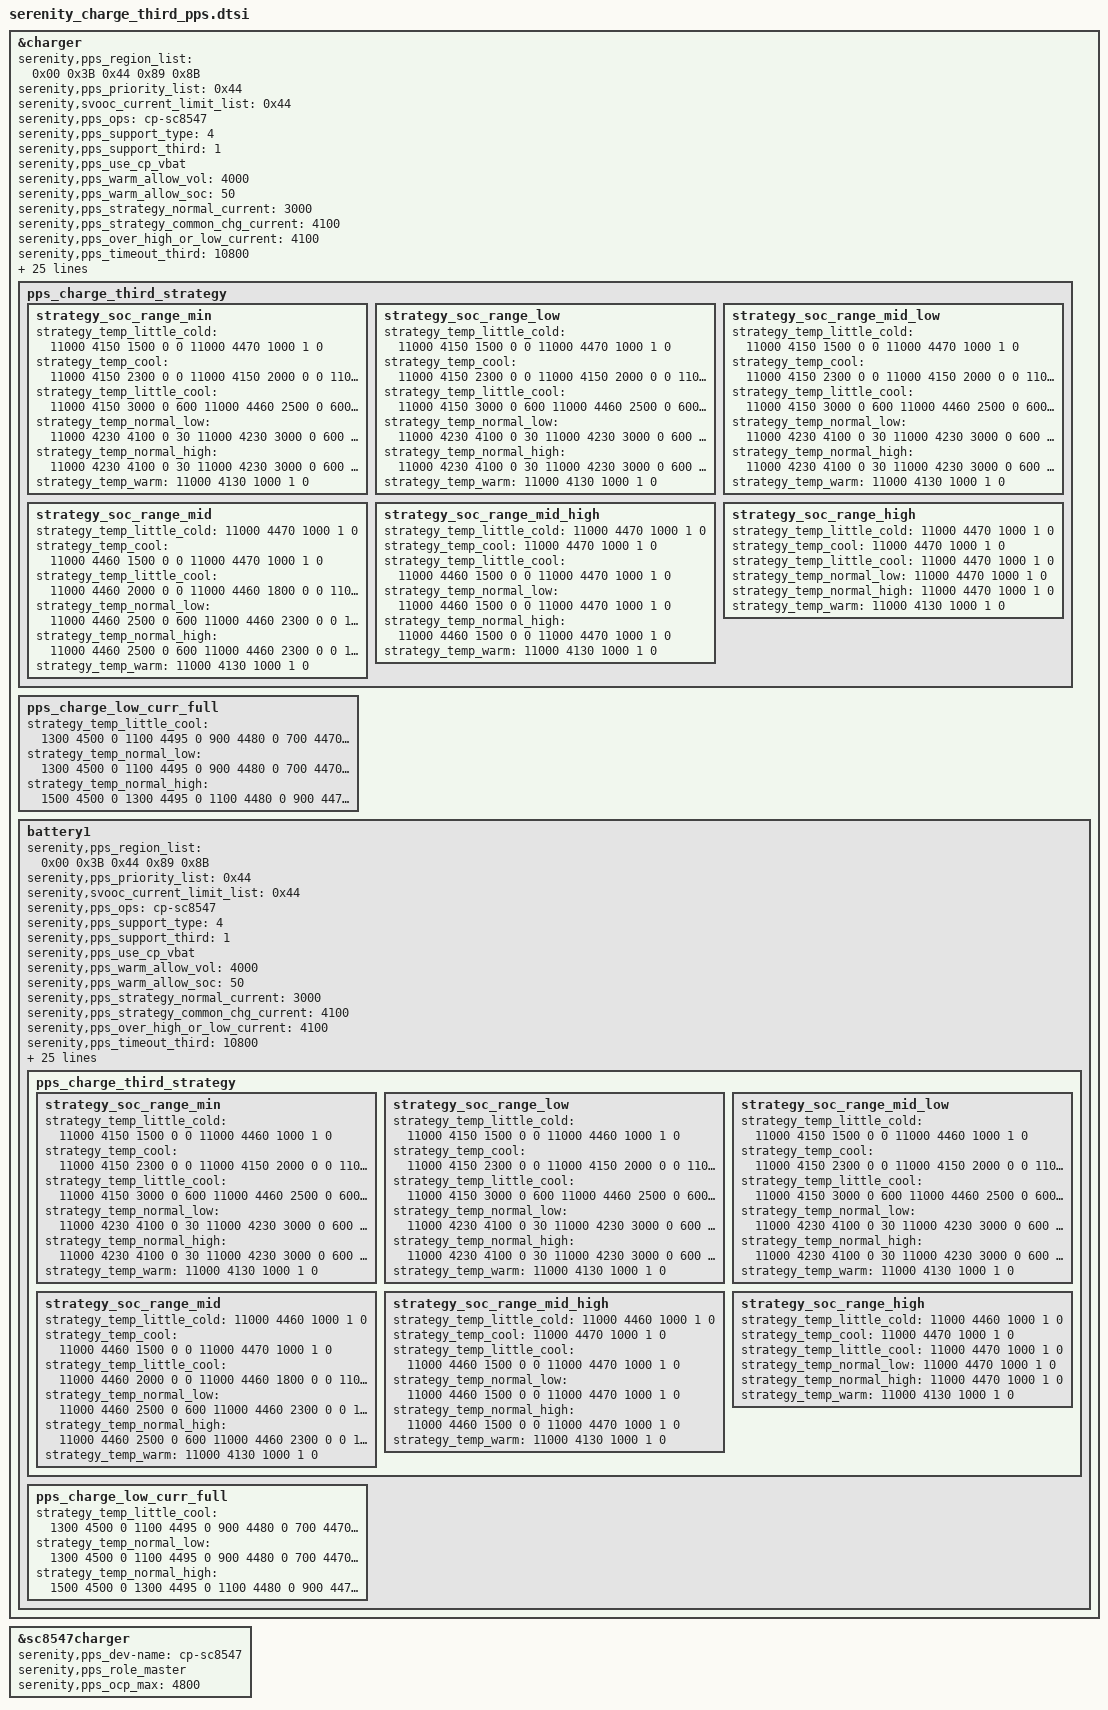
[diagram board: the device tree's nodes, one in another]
//#ifdef SERENITY_FEATURE_CHG_BASIC
&charger {
	// 3rd PPS
	serenity,pps_region_list = <0x00 0x3B 0x44 0x89 0x8B>;
	serenity,pps_priority_list = <0x44>;
	serenity,svooc_current_limit_list = <0x44>;
	serenity,pps_ops = "cp-sc8547";
	serenity,pps_support_type = <4>;
	serenity,pps_support_third = <1>;
	serenity,pps_use_cp_vbat;
	serenity,pps_warm_allow_vol = <4000>;
	serenity,pps_warm_allow_soc = <50>;
	serenity,pps_strategy_normal_current = <3000>;//3A
	serenity,pps_strategy_common_chg_current = <4100>;//4.1A
	serenity,pps_over_high_or_low_current = <4100>;
	serenity,pps_timeout_third = <10800>;
	serenity,pps_timeout_serenity = <7200>;
	serenity,pps_ibat_over_third = <8200>;
	serenity,pps_ibat_over_serenity = <17000>;
	serenity,pps_full_ffc_vbat = <4500>;
	serenity,pps_full_cool_sw_vbat = <4460>;
	serenity,pps_full_normal_sw_vbat = <4460>;
	serenity,pps_full_normal_hw_vbat = <4470>;
	serenity,pps_full_warm_vbat = <4130>;
	serenity,pps_full_cool_sw_vbat_third = <4460>;
	serenity,pps_full_normal_sw_vbat_third = <4460>;
	serenity,pps_full_normal_hw_vbat_third = <4470>;
	serenity,pps_r_default = <120 10 10 15 15 15 15>;
	serenity,pps_rmos_mohm = <4>;
	serenity,pps_exit_ms = <500>;
	serenity,pps_r_limit = <280 200 140 90 50>;
	serenity,pps_strategy_batt_high_temp = <385 395 420 375 385 410>;
	serenity,pps_strategy_high_current = <3000 3000 2000 3000 3000 3000>;
	serenity,pps_charge_strategy_soc = <0 15 35 50 75 85 90>;
	serenity,pps_charge_strategy_temp = <0 50 120 160 350 430 530>;
	serenity,pps_low_curr_full_strategy_temp = <120 200 350 430>;

	pps_charge_third_strategy {
		// 0 ~ 15
		strategy_soc_range_min {
			strategy_temp_little_cold =	<11000 4150 1500 0 0
							 11000 4470 1000 1 0>;
			strategy_temp_cool =		<11000 4150 2300 0 0
							 11000 4150 2000 0 0
							 11000 4460 1500 0 0
							 11000 4470 1000 1 0>;
			strategy_temp_little_cool =	<11000 4150 3000 0 600
							 11000 4460 2500 0 600
							 11000 4460 2300 0 0
							 11000 4460 2000 0 0
							 11000 4460 1800 0 0
							 11000 4460 1500 0 0
							 11000 4470 1000 1 0>;
			strategy_temp_normal_low =	<11000 4230 4100 0 30
							 11000 4230 3000 0 600
							 11000 4460 2500 0 600
							 11000 4460 2300 0 0
							 11000 4460 2000 0 0
							 11000 4460 1800 0 0
							 11000 4460 1500 0 0
							 11000 4470 1000 1 0>;
			strategy_temp_normal_high =	<11000 4230 4100 0 30
							 11000 4230 3000 0 600
							 11000 4460 2500 0 600
							 11000 4460 2300 0 0
							 11000 4460 2000 0 0
							 11000 4460 1800 0 0
							 11000 4460 1500 0 0
							 11000 4470 1000 1 0>;
			strategy_temp_warm =		<11000 4130 1000 1 0>;
		};
		// 15 ~ 35
		strategy_soc_range_low {
			strategy_temp_little_cold =	<11000 4150 1500 0 0
							 11000 4470 1000 1 0>;
			strategy_temp_cool =		<11000 4150 2300 0 0
							 11000 4150 2000 0 0
							 11000 4460 1500 0 0
							 11000 4470 1000 1 0>;
			strategy_temp_little_cool =	<11000 4150 3000 0 600
							 11000 4460 2500 0 600
							 11000 4460 2300 0 0
							 11000 4460 2000 0 0
							 11000 4460 1800 0 0
							 11000 4460 1500 0 0
							 11000 4470 1000 1 0>;
			strategy_temp_normal_low =	<11000 4230 4100 0 30
							 11000 4230 3000 0 600
							 11000 4460 2500 0 600
							 11000 4460 2300 0 0
							 11000 4460 2000 0 0
							 11000 4460 1800 0 0
							 11000 4460 1500 0 0
							 11000 4470 1000 1 0>;
			strategy_temp_normal_high =	<11000 4230 4100 0 30
							 11000 4230 3000 0 600
							 11000 4460 2500 0 600
							 11000 4460 2300 0 0
							 11000 4460 2000 0 0
							 11000 4460 1800 0 0
							 11000 4460 1500 0 0
							 11000 4470 1000 1 0>;
			strategy_temp_warm =		<11000 4130 1000 1 0>;
		};
		// 35 ~ 50
		strategy_soc_range_mid_low {
			strategy_temp_little_cold =	<11000 4150 1500 0 0
							 11000 4470 1000 1 0>;
			strategy_temp_cool =		<11000 4150 2300 0 0
							 11000 4150 2000 0 0
							 11000 4460 1500 0 0
							 11000 4470 1000 1 0>;
			strategy_temp_little_cool =	<11000 4150 3000 0 600
							 11000 4460 2500 0 600
							 11000 4460 2300 0 0
							 11000 4460 2000 0 0
							 11000 4460 1800 0 0
							 11000 4460 1500 0 0
							 11000 4470 1000 1 0>;
			strategy_temp_normal_low =	<11000 4230 4100 0 30
							 11000 4230 3000 0 600
							 11000 4460 2500 0 600
							 11000 4460 2300 0 0
							 11000 4460 2000 0 0
							 11000 4460 1800 0 0
							 11000 4460 1500 0 0
							 11000 4470 1000 1 0>;
			strategy_temp_normal_high =	<11000 4230 4100 0 30
							 11000 4230 3000 0 600
							 11000 4460 2500 0 600
							 11000 4460 2300 0 0
							 11000 4460 2000 0 0
							 11000 4460 1800 0 0
							 11000 4460 1500 0 0
							 11000 4470 1000 1 0>;
			strategy_temp_warm =		<11000 4130 1000 1 0>;
		};
		// 50 ~ 75
		strategy_soc_range_mid {
			strategy_temp_little_cold =	<11000 4470 1000 1 0>;
			strategy_temp_cool =		<11000 4460 1500 0 0
							 11000 4470 1000 1 0>;
			strategy_temp_little_cool =	<11000 4460 2000 0 0
							 11000 4460 1800 0 0
							 11000 4460 1500 0 0
							 11000 4470 1000 1 0>;
			strategy_temp_normal_low =	<11000 4460 2500 0 600
							 11000 4460 2300 0 0
							 11000 4460 2000 0 0
							 11000 4460 1800 0 0
							 11000 4460 1500 0 0
							 11000 4470 1000 1 0>;
			strategy_temp_normal_high =	<11000 4460 2500 0 600
							 11000 4460 2300 0 0
							 11000 4460 2000 0 0
							 11000 4460 1800 0 0
							 11000 4460 1500 0 0
							 11000 4470 1000 1 0>;
			strategy_temp_warm =		<11000 4130 1000 1 0>;
		};
		// 75 ~ 85
		strategy_soc_range_mid_high {
			strategy_temp_little_cold =	<11000 4470 1000 1 0>;
			strategy_temp_cool =		<11000 4470 1000 1 0>;
			strategy_temp_little_cool =	<11000 4460 1500 0 0
							 11000 4470 1000 1 0>;
			strategy_temp_normal_low =	<11000 4460 1500 0 0
							 11000 4470 1000 1 0>;
			strategy_temp_normal_high =	<11000 4460 1500 0 0
							 11000 4470 1000 1 0>;
			strategy_temp_warm =		<11000 4130 1000 1 0>;
		};
		// 85 ~ 90
		strategy_soc_range_high {
			strategy_temp_little_cold =	<11000 4470 1000 1 0>;
			strategy_temp_cool =		<11000 4470 1000 1 0>;
			strategy_temp_little_cool =	<11000 4470 1000 1 0>;
			strategy_temp_normal_low =	<11000 4470 1000 1 0>;
			strategy_temp_normal_high =	<11000 4470 1000 1 0>;
			strategy_temp_warm =		<11000 4130 1000 1 0>;
		};
	};
	pps_charge_low_curr_full {
		strategy_temp_little_cool = 	<1300 4500 0
						 1100 4495 0
						 900 4480 0
						 700 4470 0
						 500 4460 1>;
		strategy_temp_normal_low =		<1300 4500 0
						 1100 4495 0
						 900 4480 0
						 700 4470 0
						 500 4460 1>;
		strategy_temp_normal_high = 	<1500 4500 0
						 1300 4495 0
						 1100 4480 0
						 900 4470 0
						 700 4460 1>;
	};
};

&charger {
	battery1 {
		// 3rd PPS
		serenity,pps_region_list = <0x00 0x3B 0x44 0x89 0x8B>;
		serenity,pps_priority_list = <0x44>;
		serenity,svooc_current_limit_list = <0x44>;
		serenity,pps_ops = "cp-sc8547";
		serenity,pps_support_type = <4>;
		serenity,pps_support_third = <1>;
		serenity,pps_use_cp_vbat;
		serenity,pps_warm_allow_vol = <4000>;
		serenity,pps_warm_allow_soc = <50>;
		serenity,pps_strategy_normal_current = <3000>;//3A
		serenity,pps_strategy_common_chg_current = <4100>;//4.1A
		serenity,pps_over_high_or_low_current = <4100>;
		serenity,pps_timeout_third = <10800>;
		serenity,pps_timeout_serenity = <7200>;
		serenity,pps_ibat_over_third = <8200>;
		serenity,pps_ibat_over_serenity = <17000>;
		serenity,pps_full_ffc_vbat = <4500>;
		serenity,pps_full_cool_sw_vbat = <4460>;
		serenity,pps_full_normal_sw_vbat = <4460>;
		serenity,pps_full_normal_hw_vbat = <4470>;
		serenity,pps_full_warm_vbat = <4130>;
		serenity,pps_full_cool_sw_vbat_third = <4460>;
		serenity,pps_full_normal_sw_vbat_third = <4460>;
		serenity,pps_full_normal_hw_vbat_third = <4470>;
		serenity,pps_r_default = <120 10 10 15 15 15 15>;
		serenity,pps_rmos_mohm = <4>;
		serenity,pps_exit_ms = <500>;
		serenity,pps_r_limit = <280 200 140 90 50>;
		serenity,pps_strategy_batt_high_temp = <385 395 420 375 385 410>;
		serenity,pps_strategy_high_current = <3000 3000 2000 3000 3000 3000>;
		serenity,pps_charge_strategy_soc = <0 15 35 50 75 85 90>;
		serenity,pps_charge_strategy_temp = <0 50 120 160 350 430 530>;
		serenity,pps_low_curr_full_strategy_temp = <120 200 350 430>;

		pps_charge_third_strategy {
			// 0 ~ 15
			strategy_soc_range_min {
				strategy_temp_little_cold =	<11000 4150 1500 0 0
								11000 4460 1000 1 0>;
				strategy_temp_cool =		<11000 4150 2300 0 0
								11000 4150 2000 0 0
								11000 4460 1500 0 0
								11000 4470 1000 1 0>;
				strategy_temp_little_cool =	<11000 4150 3000 0 600
								11000 4460 2500 0 600
								11000 4460 2300 0 0
								11000 4460 2000 0 0
								11000 4460 1800 0 0
								11000 4460 1500 0 0
								11000 4470 1000 1 0>;
				strategy_temp_normal_low =	<11000 4230 4100 0 30
								11000 4230 3000 0 600
								11000 4460 2500 0 600
								11000 4460 2300 0 0
								11000 4460 2000 0 0
								11000 4460 1800 0 0
								11000 4460 1500 0 0
								11000 4470 1000 1 0>;
				strategy_temp_normal_high =	<11000 4230 4100 0 30
								11000 4230 3000 0 600
								11000 4460 2500 0 600
								11000 4460 2300 0 0
								11000 4460 2000 0 0
								11000 4460 1800 0 0
								11000 4460 1500 0 0
								11000 4470 1000 1 0>;
				strategy_temp_warm =		<11000 4130 1000 1 0>;
			};
			// 15 ~ 35
			strategy_soc_range_low {
				strategy_temp_little_cold =	<11000 4150 1500 0 0
								11000 4460 1000 1 0>;
				strategy_temp_cool =		<11000 4150 2300 0 0
								11000 4150 2000 0 0
								11000 4460 1500 0 0
								11000 4470 1000 1 0>;
				strategy_temp_little_cool =	<11000 4150 3000 0 600
								11000 4460 2500 0 600
								11000 4460 2300 0 0
								11000 4460 2000 0 0
								11000 4460 1800 0 0
								11000 4460 1500 0 0
								11000 4470 1000 1 0>;
				strategy_temp_normal_low =	<11000 4230 4100 0 30
								11000 4230 3000 0 600
								11000 4460 2500 0 600
								11000 4460 2300 0 0
								11000 4460 2000 0 0
								11000 4460 1800 0 0
								11000 4460 1500 0 0
								11000 4470 1000 1 0>;
				strategy_temp_normal_high =	<11000 4230 4100 0 30
								11000 4230 3000 0 600
								11000 4460 2500 0 600
								11000 4460 2300 0 0
								11000 4460 2000 0 0
								11000 4460 1800 0 0
								11000 4460 1500 0 0
								11000 4470 1000 1 0>;
				strategy_temp_warm =		<11000 4130 1000 1 0>;
			};
			// 35 ~ 50
			strategy_soc_range_mid_low {
				strategy_temp_little_cold =	<11000 4150 1500 0 0
								11000 4460 1000 1 0>;
				strategy_temp_cool =		<11000 4150 2300 0 0
								11000 4150 2000 0 0
								11000 4460 1500 0 0
								11000 4470 1000 1 0>;
				strategy_temp_little_cool =	<11000 4150 3000 0 600
								11000 4460 2500 0 600
								11000 4460 2300 0 0
								11000 4460 2000 0 0
								11000 4460 1800 0 0
								11000 4460 1500 0 0
								11000 4470 1000 1 0>;
				strategy_temp_normal_low =	<11000 4230 4100 0 30
								11000 4230 3000 0 600
								11000 4460 2500 0 600
								11000 4460 2300 0 0
								11000 4460 2000 0 0
								11000 4460 1800 0 0
								11000 4460 1500 0 0
								11000 4470 1000 1 0>;
				strategy_temp_normal_high =	<11000 4230 4100 0 30
								11000 4230 3000 0 600
								11000 4460 2500 0 600
								11000 4460 2300 0 0
								11000 4460 2000 0 0
								11000 4460 1800 0 0
								11000 4460 1500 0 0
								11000 4470 1000 1 0>;
				strategy_temp_warm =		<11000 4130 1000 1 0>;
			};
			// 50 ~ 75
			strategy_soc_range_mid {
				strategy_temp_little_cold =	<11000 4460 1000 1 0>;
				strategy_temp_cool =		<11000 4460 1500 0 0
								11000 4470 1000 1 0>;
				strategy_temp_little_cool =	<11000 4460 2000 0 0
								11000 4460 1800 0 0
								11000 4460 1500 0 0
								11000 4470 1000 1 0>;
				strategy_temp_normal_low =	<11000 4460 2500 0 600
								11000 4460 2300 0 0
								11000 4460 2000 0 0
								11000 4460 1800 0 0
								11000 4460 1500 0 0
								11000 4470 1000 1 0>;
				strategy_temp_normal_high =	<11000 4460 2500 0 600
								11000 4460 2300 0 0
								11000 4460 2000 0 0
								11000 4460 1800 0 0
								11000 4460 1500 0 0
								11000 4470 1000 1 0>;
				strategy_temp_warm =		<11000 4130 1000 1 0>;
			};
			// 75 ~ 85
			strategy_soc_range_mid_high {
				strategy_temp_little_cold =	<11000 4460 1000 1 0>;
				strategy_temp_cool =		<11000 4470 1000 1 0>;
				strategy_temp_little_cool =	<11000 4460 1500 0 0
								11000 4470 1000 1 0>;
				strategy_temp_normal_low =	<11000 4460 1500 0 0
								11000 4470 1000 1 0>;
				strategy_temp_normal_high =	<11000 4460 1500 0 0
								11000 4470 1000 1 0>;
				strategy_temp_warm =		<11000 4130 1000 1 0>;
			};
			// 85 ~ 90
			strategy_soc_range_high {
				strategy_temp_little_cold =	<11000 4460 1000 1 0>;
				strategy_temp_cool =		<11000 4470 1000 1 0>;
				strategy_temp_little_cool =	<11000 4470 1000 1 0>;
				strategy_temp_normal_low =	<11000 4470 1000 1 0>;
				strategy_temp_normal_high =	<11000 4470 1000 1 0>;
				strategy_temp_warm =		<11000 4130 1000 1 0>;
			};
		};
		pps_charge_low_curr_full {
			strategy_temp_little_cool = 	<1300 4500 0
							1100 4495 0
							900 4480 0
							700 4470 0
							500 4460 1>;
			strategy_temp_normal_low =		<1300 4500 0
							1100 4495 0
							900 4480 0
							700 4470 0
							500 4460 1>;
			strategy_temp_normal_high = 	<1500 4500 0
							1300 4495 0
							1100 4480 0
							900 4470 0
							700 4460 1>;
		};
	};
};
&sc8547charger {
	serenity,pps_dev-name = "cp-sc8547";
	serenity,pps_role_master;
	serenity,pps_ocp_max = <4800>;
};
//#endif /*SERENITY_FEATURE_CHG_BASIC*/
